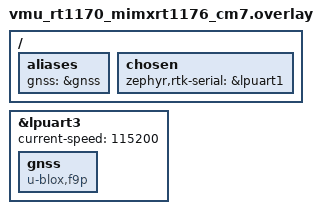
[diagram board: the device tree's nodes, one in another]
/*
 * Copyright 2024 (c) NXP
 * Copyright 2025 (c) Croxel Inc.
 * Copyright 2025 (c) CogniPilot Foundation
 *
 * SPDX-License-Identifier: Apache-2.0
 */

/ {
	aliases {
		gnss = &gnss;
	};
	chosen {
		zephyr,rtk-serial = &lpuart1;
	};
};

&lpuart3 {
	status = "okay";
	current-speed = <115200>;

	gnss: gnss {
		status = "okay";
		compatible = "u-blox,f9p";
	};
};
